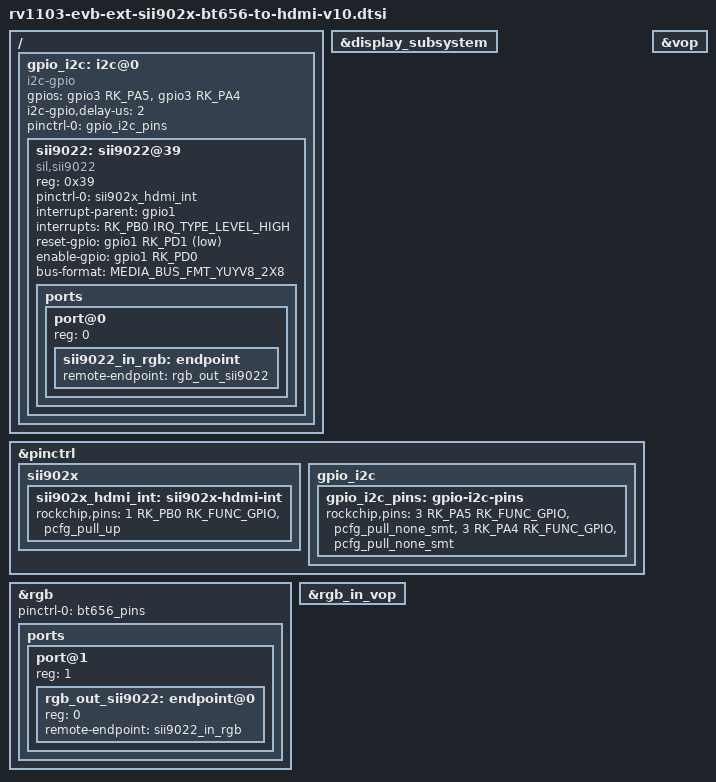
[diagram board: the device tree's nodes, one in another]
// SPDX-License-Identifier: (GPL-2.0+ OR MIT)
/*
 * Copyright (c) 2022 Rockchip Electronics Co., Ltd.
 */

#include <dt-bindings/display/media-bus-format.h>

/ {
	gpio_i2c: i2c@0 {
		compatible = "i2c-gpio";
		gpios = <&gpio3 RK_PA5 GPIO_ACTIVE_HIGH>, /* sda */
			<&gpio3 RK_PA4 GPIO_ACTIVE_HIGH>; /* scl */
		i2c-gpio,delay-us = <2>;		  /* ~100 kHz */
		#address-cells = <1>;
		#size-cells = <0>;
		pinctrl-names = "default";
		pinctrl-0 = <&gpio_i2c_pins>;
		status = "okay";

		sii9022: sii9022@39 {
			compatible = "sil,sii9022";
			reg = <0x39>;
			pinctrl-names = "default";
			pinctrl-0 = <&sii902x_hdmi_int>;
			interrupt-parent = <&gpio1>;
			interrupts = <RK_PB0 IRQ_TYPE_LEVEL_HIGH>;
			reset-gpio = <&gpio1 RK_PD1 GPIO_ACTIVE_LOW>;
			enable-gpio = <&gpio1 RK_PD0 GPIO_ACTIVE_HIGH>;
			/*
			 * MEDIA_BUS_FMT_YUYV8_1X16 for bt1120
			 * MEDIA_BUS_FMT_YUYV8_2X8  for bt656
			 */
			bus-format = <MEDIA_BUS_FMT_YUYV8_2X8>;

			ports {
			#address-cells = <1>;
			#size-cells = <0>;

				port@0 {
					reg = <0>;

					sii9022_in_rgb: endpoint {
						remote-endpoint = <&rgb_out_sii9022>;
					};
				};
			};
		};
	};
};

&display_subsystem {
	status = "okay";
};

&pinctrl {
	sii902x {
		sii902x_hdmi_int: sii902x-hdmi-int {
			rockchip,pins = <1 RK_PB0 RK_FUNC_GPIO &pcfg_pull_up>;
		};
	};

	gpio_i2c {
		gpio_i2c_pins: gpio-i2c-pins {
			rockchip,pins =
				/* gpio_i2c_sda */
				<3 RK_PA5 RK_FUNC_GPIO &pcfg_pull_none_smt>,
				/* gpio_i2c_scl */
				<3 RK_PA4 RK_FUNC_GPIO &pcfg_pull_none_smt>;
		};
	};
};

&rgb {
	status = "okay";
	pinctrl-names = "default";
	pinctrl-0 = <&bt656_pins>;

	ports {
		port@1 {
			reg = <1>;
			#address-cells = <1>;
			#size-cells = <0>;

			rgb_out_sii9022: endpoint@0 {
				reg = <0>;
				remote-endpoint = <&sii9022_in_rgb>;
			};
		};
	};
};

&rgb_in_vop {
	status = "okay";
};

&vop {
	status = "okay";
};
